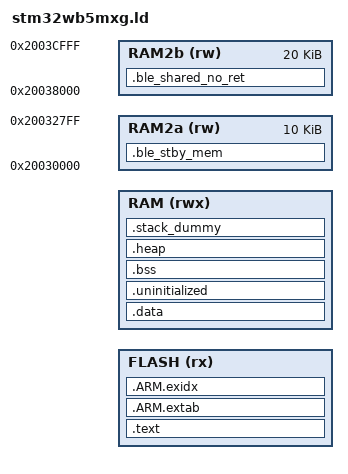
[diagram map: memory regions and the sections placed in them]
/* Linker script to configure memory regions. */
/*
 * SPDX-License-Identifier: BSD-3-Clause
 ******************************************************************************
 * @attention
 *
 * Copyright (c) 2016-2020 STMicroelectronics.
 * All rights reserved.
 *
 * This software component is licensed by ST under BSD 3-Clause license,
 * the "License"; You may not use this file except in compliance with the
 * License. You may obtain a copy of the License at:
 *                        opensource.org/licenses/BSD-3-Clause
 *
 ******************************************************************************
*/

#include "../cmsis_nvic.h"


#if !defined(MBED_APP_START)
  #define MBED_APP_START  MBED_ROM_START
#endif

#if !defined(MBED_APP_SIZE)
// MBED_APP_SIZE cannot be full ROM size as core M0 FW is using the end of FLASH
// Size is defined in json with "mbed_rom_size"
#define MBED_APP_SIZE MBED_ROM_SIZE
#endif

#if !defined(MBED_CONF_TARGET_BOOT_STACK_SIZE)
    /* This value is normally defined by the tools
       to 0x1000 for bare metal and 0x400 for RTOS */
    #define MBED_CONF_TARGET_BOOT_STACK_SIZE  0x400
#endif

/* Round up VECTORS_SIZE to 8 bytes */
#define VECTORS_SIZE  (((NVIC_NUM_VECTORS * 4) + 7) & 0xFFFFFFF8)

/* RAM_SIZE = 192KB SRAM1 (0x30000) + Shared mem (part of SRAM2) */
MEMORY
{ 
  FLASH (rx) : ORIGIN = MBED_APP_START, LENGTH = MBED_APP_SIZE
  RAM (rwx)   : ORIGIN = MBED_RAM_START + VECTORS_SIZE, LENGTH = 0x30000 - VECTORS_SIZE
  RAM2a (rw)  : ORIGIN = 0x20030000, LENGTH = 10K
  RAM2b (rw)  : ORIGIN = 0x20038000, LENGTH = 20K
}

/* Linker script to place sections and symbol values. Should be used together
 * with other linker script that defines memory regions FLASH and RAM.
 * It references following symbols, which must be defined in code:
 *   Reset_Handler : Entry of reset handler
 *
 * It defines following symbols, which code can use without definition:
 *   __exidx_start
 *   __exidx_end
 *   __etext
 *   __data_start__
 *   __preinit_array_start
 *   __preinit_array_end
 *   __init_array_start
 *   __init_array_end
 *   __fini_array_start
 *   __fini_array_end
 *   __data_end__
 *   __bss_start__
 *   __bss_end__
 *   __end__
 *   end
 *   __HeapLimit
 *   __StackLimit
 *   __StackTop
 *   __stack
 *   _estack
 */
ENTRY(Reset_Handler)

SECTIONS
{
    .text :
    {
        KEEP(*(.isr_vector))
        *(.text*)

        KEEP(*(.init))
        KEEP(*(.fini))

        /* .ctors */
        *crtbegin.o(.ctors)
        *crtbegin?.o(.ctors)
        *(EXCLUDE_FILE(*crtend?.o *crtend.o) .ctors)
        *(SORT(.ctors.*))
        *(.ctors)

        /* .dtors */
        *crtbegin.o(.dtors)
        *crtbegin?.o(.dtors)
        *(EXCLUDE_FILE(*crtend?.o *crtend.o) .dtors)
        *(SORT(.dtors.*))
        *(.dtors)

        *(.rodata*)

        KEEP(*(.eh_frame*))
    } > FLASH

    .ARM.extab :
    {
        *(.ARM.extab* .gnu.linkonce.armextab.*)
    } > FLASH

    __exidx_start = .;
    .ARM.exidx :
    {
        *(.ARM.exidx* .gnu.linkonce.armexidx.*)
    } > FLASH
    __exidx_end = .;

    __etext = .;
    _sidata = .;
    
    .data : AT (__etext)
    {
        __data_start__ = .;
        _sdata = .;
        *(vtable)
        *(.data*)

        . = ALIGN(8);
        /* preinit data */
        PROVIDE_HIDDEN (__preinit_array_start = .);
        KEEP(*(.preinit_array))
        PROVIDE_HIDDEN (__preinit_array_end = .);

        . = ALIGN(8);
        /* init data */
        PROVIDE_HIDDEN (__init_array_start = .);
        KEEP(*(SORT(.init_array.*)))
        KEEP(*(.init_array))
        PROVIDE_HIDDEN (__init_array_end = .);

        . = ALIGN(8);
        /* finit data */
        PROVIDE_HIDDEN (__fini_array_start = .);
        KEEP(*(SORT(.fini_array.*)))
        KEEP(*(.fini_array))
        PROVIDE_HIDDEN (__fini_array_end = .);

        KEEP(*(.jcr*))
        . = ALIGN(8);
        /* All data end */
        __data_end__ = .;
        _edata = .;

    } > RAM

    /* Uninitialized data section
     * This region is not initialized by the C/C++ library and can be used to
     * store state across soft reboots. */
    .uninitialized (NOLOAD):
    {
        . = ALIGN(32);
        __uninitialized_start = .;
        *(.uninitialized)
        KEEP(*(.keep.uninitialized))
        . = ALIGN(32);
        __uninitialized_end = .;
    } > RAM
    
    .bss :
    {
        . = ALIGN(8);
        __bss_start__ = .;
        _sbss = .;
        *(.bss*)
        *(COMMON)
        . = ALIGN(8);
        __bss_end__ = .;
        _ebss = .;
    } > RAM

    .heap (COPY):
    {
        __end__ = .;
        PROVIDE(end = .);
        *(.heap*)
        . = ORIGIN(RAM) + LENGTH(RAM) - MBED_CONF_TARGET_BOOT_STACK_SIZE;
        __HeapLimit = .;
    } > RAM

    /* .stack_dummy section doesn't contains any symbols. It is only
     * used for linker to calculate size of stack sections, and assign
     * values to stack symbols later */
    .stack_dummy (COPY):
    {
        *(.stack*)
    } > RAM

    .ble_stby_mem (NOLOAD) :
    {
      *(MAPPING_TABLE);
      *(MB_MEM1);
    } >RAM2a

    .ble_shared_no_ret (NOLOAD) :
    {
      _sMB_MEM2 = . ;
      *(MB_MEM2);
      _eMB_MEM2 = . ;
    } >RAM2b

    /* Set stack top to end of RAM, and stack limit move down by
     * size of stack_dummy section */
    __StackTop = ORIGIN(RAM) + LENGTH(RAM);
    _estack = __StackTop;
    __StackLimit = __StackTop - MBED_CONF_TARGET_BOOT_STACK_SIZE;
    PROVIDE(__stack = __StackTop);

    /* Check if data + heap + stack exceeds RAM limit */
    ASSERT(__StackLimit >= __HeapLimit, "region RAM overflowed with stack")
}
